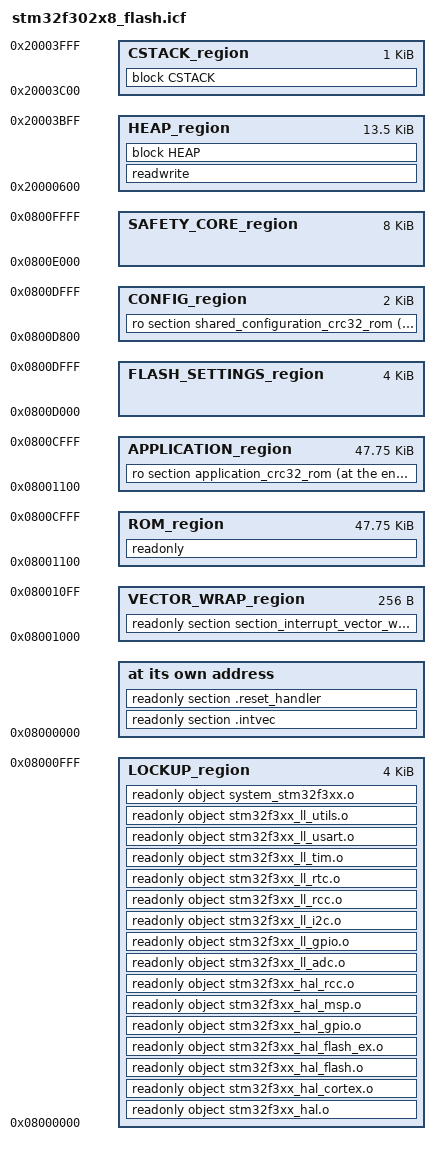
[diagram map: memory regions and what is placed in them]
/*-Specials-*/
define symbol __ICFEDIT_intvec_start__ = 0x08000000;

/*-Flash Memory Regions-*/
define symbol __ICFEDIT_region_LOCKUP_start__              = 0x08000000; 
define symbol __ICFEDIT_region_LOCKUP_end__                = 0x08000FFF;
define symbol __ICFEDIT_region_INT_VEC_WRAP_start__        = 0x08001000;
define symbol __ICFEDIT_region_INT_VEC_WRAP_end__          = 0x080010FF;
define symbol __ICFEDIT_region_ROM_start__                 = 0x08001100;
define symbol __ICFEDIT_region_ROM_end__                   = 0x0800CFFF;
define symbol __ICFEDIT_region_FLASH_SETTINGS_MAIN_start__ = 0x0800D000;
define symbol __ICFEDIT_region_FLASH_SETTINGS_MAIN_end__   = 0x0800D7FF;
define symbol __ICFEDIT_region_FLASH_SETTINGS_COPY_start__ = 0x0800D800;
define symbol __ICFEDIT_region_FLASH_SETTINGS_COPY_end__   = 0x0800DFFF;
define symbol __ICFEDIT_region_SAFETY_CORE_start__         = 0x0800E000; 
define symbol __ICFEDIT_region_SAFETY_CORE_end__           = 0x0800FFFF;

/*-RAM sizes-*/
define symbol __ICFEDIT_size_cstack__ = 0x400;
define symbol __ICFEDIT_size_heap__ = 0x3600; 
/*-RAM Memory Regions-*/   
define symbol __ICFEDIT_region_SAFETY_RAM_start__ = 0x20000000;
define symbol __ICFEDIT_region_SAFETY_RAM_end__   = 0x200005FF;  
define symbol __ICFEDIT_region_HEAP_start__       = 0x20000600;
define symbol __ICFEDIT_region_HEAP_end__         = 0x20003BFF;
define symbol __ICFEDIT_region_CSTACK_start__     = 0x20003C00;
define symbol __ICFEDIT_region_CSTACK_end__       = 0x20003FFF;


define memory mem with size = 4G;

//LOCKUP_region contains Bootloader Brickproofing Code, interrupt vectors and ST Drivers that will not change
define region LOCKUP_region      = mem:[from __ICFEDIT_region_LOCKUP_start__ to __ICFEDIT_region_LOCKUP_end__];

//VECTOR_WRAP_region contains wrappers for interrupt vectors 
define region VECTOR_WRAP_region  = mem:[from __ICFEDIT_region_INT_VEC_WRAP_start__ to __ICFEDIT_region_INT_VEC_WRAP_end__];

//ROM_region contains executable code
define region ROM_region           = mem:[from __ICFEDIT_region_ROM_start__ to __ICFEDIT_region_ROM_end__];

//FLASH_SETTINGS_region is two pages for permanent storage of parameters
define region FLASH_SETTINGS_region = mem:[from __ICFEDIT_region_FLASH_SETTINGS_MAIN_start__ to __ICFEDIT_region_FLASH_SETTINGS_COPY_end__ ];

//SAFETY_CORE_region  for meerkat
define region SAFETY_CORE_region = mem:[from __ICFEDIT_region_SAFETY_CORE_start__ to __ICFEDIT_region_SAFETY_CORE_end__ ];


define region CSTACK_region = mem:[from __ICFEDIT_region_CSTACK_start__ to __ICFEDIT_region_CSTACK_end__];
define region HEAP_region   = mem:[from __ICFEDIT_region_HEAP_start__ to __ICFEDIT_region_HEAP_end__];

define block CSTACK    with alignment = 8, size = __ICFEDIT_size_cstack__   { };
define block HEAP      with alignment = 8, size = __ICFEDIT_size_heap__     { };

initialize by copy { readwrite };
do not initialize  { section .noinit };

place at address mem:__ICFEDIT_region_LOCKUP_start__ {readonly section .intvec,
                                                      readonly section .reset_handler};

place in LOCKUP_region { readonly object stm32f3xx_hal.o,
			 readonly object stm32f3xx_hal_cortex.o,
			 readonly object stm32f3xx_hal_flash.o,
			 readonly object stm32f3xx_hal_flash_ex.o,
			 readonly object stm32f3xx_hal_gpio.o,
			 readonly object stm32f3xx_hal_msp.o,
			 readonly object stm32f3xx_hal_rcc.o,
			 readonly object stm32f3xx_ll_adc.o,
			 readonly object stm32f3xx_ll_gpio.o,
			 readonly object stm32f3xx_ll_i2c.o,
			 readonly object stm32f3xx_ll_rcc.o,
			 readonly object stm32f3xx_ll_rtc.o,
		         readonly object stm32f3xx_ll_tim.o,
			 readonly object stm32f3xx_ll_usart.o,
			 readonly object stm32f3xx_ll_utils.o,
			 readonly object system_stm32f3xx.o };


place in VECTOR_WRAP_region {readonly section section_interrupt_vector_wrappers};

place in ROM_region   { readonly };

place in HEAP_region   { readwrite, block HEAP };
place in CSTACK_region { block CSTACK};

// CRC Calculation Extensions
// - Shared Configuration Area
define region CONFIG_region      = mem:[from __ICFEDIT_region_FLASH_SETTINGS_COPY_start__   to __ICFEDIT_region_FLASH_SETTINGS_COPY_end__];
place at end of CONFIG_region { ro section shared_configuration_crc32_rom };
// - Application Configuration Area
define region APPLICATION_region      = mem:[from __ICFEDIT_region_ROM_start__   to __ICFEDIT_region_ROM_end__];
place at end of APPLICATION_region { ro section application_crc32_rom };
// -- Shared Configuration ROM Space
define symbol LNK_CFG_ROM_START = __ICFEDIT_region_FLASH_SETTINGS_COPY_start__;
export symbol LNK_CFG_ROM_START;
define symbol LNK_CFG_ROM_END = __ICFEDIT_region_FLASH_SETTINGS_COPY_end__;
export symbol LNK_CFG_ROM_END;
// -- Application Firmware ROM Space (will be overwritten by Application Firmware)
define symbol LNK_APP_ROM_START = __ICFEDIT_region_ROM_start__;
export symbol LNK_APP_ROM_START;
define symbol LNK_APP_ROM_END = __ICFEDIT_region_ROM_end__;
export symbol LNK_APP_ROM_END;
define symbol LNK_APP_ROM_CRC = __ICFEDIT_region_ROM_end__-3; // -3 because is a four byte value, at which ROM_end points to the last of
export symbol LNK_APP_ROM_CRC;
